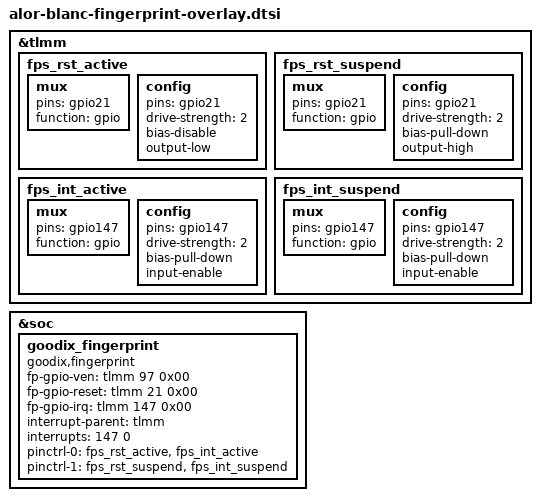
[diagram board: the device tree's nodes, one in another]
/* Copyright (c) 2025 Motorola Mobility LLC. All rights reserved.
 *
 * This program is free software; you can redistribute it and/or modify
 * it under the terms of the GNU General Public License version 2 and
 * only version 2 as published by the Free Software Foundation.
 *
 * This program is distributed in the hope that it will be useful,
 * but WITHOUT ANY WARRANTY; without even the implied warranty of
 * MERCHANTABILITY or FITNESS FOR A PARTICULAR PURPOSE.  See the
 * GNU General Public License for more details.
 */

#include <dt-bindings/regulator/qcom,rpmh-regulator-levels.h>

&tlmm {

	fps_rst_active: fps_rst_active {
			/* RESET */
			mux {
				pins = "gpio21";
				function = "gpio";
			};
			config {
				pins = "gpio21";
				drive-strength = <2>; /* 2 MA */
				bias-disable;
				output-low;
			};
	};

	fps_rst_suspend: fps_rst_suspend {
		/* sleep state */
		mux {
			pins = "gpio21";
			function = "gpio";
		};

		config {
			pins = "gpio21";
			drive-strength = <2>; /* 2 MA */
			bias-pull-down; /* pull down */
			output-high;
		};
	};

	fps_int_active: fps_int_active {
		/* active state */
		mux {
			pins = "gpio147";
			function = "gpio";
		};

		config {
			pins = "gpio147";
			drive-strength = <2>; /* 2 MA */
			bias-pull-down; /* pull down */
			input-enable;
		};
	};

	fps_int_suspend: fps_int_suspend {
		/* sleep state */
		mux {
			pins = "gpio147";
			function = "gpio";
		};

		config {
			pins = "gpio147";
			drive-strength = <2>; /* 2 MA */
			bias-pull-down; /* pull down */
			input-enable;
		};
	};

};


&soc {
	goodix_fingerprint {
		compatible = "goodix,fingerprint";
		status = "ok";
		//VBOB1->FPS VDD-> GPIO97 switcher
		fp-gpio-ven = <&tlmm 97 0x00>;
		fp-gpio-reset = <&tlmm 21 0x00>;
		fp-gpio-irq = <&tlmm 147 0x00>;
		interrupt-parent = <&tlmm>;
		interrupts = <147 0>;
		pinctrl-names = "default", "suspend";
		pinctrl-0 = <&fps_rst_active &fps_int_active>;
		pinctrl-1 = <&fps_rst_suspend &fps_int_suspend>;
	};

};
